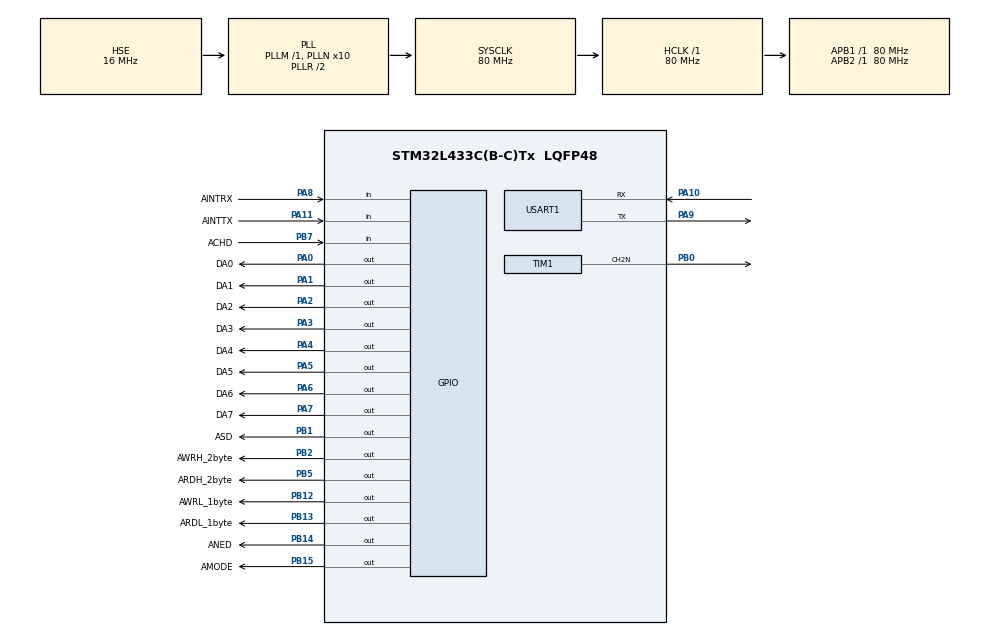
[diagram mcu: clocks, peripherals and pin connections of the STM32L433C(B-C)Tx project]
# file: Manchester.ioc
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Mcu.Family=STM32L4
Mcu.Name=STM32L433C(B-C)Tx
Mcu.Package=LQFP48
NVIC.PriorityGroup=NVIC_PRIORITYGROUP_4
PA0.GPIO_Label=DA0
PA0.Signal=GPIO_Output
PA1.GPIO_Label=DA1
PA1.Signal=GPIO_Output
PA10.Mode=Asynchronous
PA10.Signal=USART1_RX
PA11.GPIO_Label=AINTTX
PA11.Signal=GPIO_Input
PA2.GPIO_Label=DA2
PA2.Signal=GPIO_Output
PA3.GPIO_Label=DA3
PA3.Signal=GPIO_Output
PA4.GPIO_Label=DA4
PA4.Signal=GPIO_Output
PA5.GPIO_Label=DA5
PA5.Signal=GPIO_Output
PA6.GPIO_Label=DA6
PA6.Signal=GPIO_Output
PA7.GPIO_Label=DA7
PA7.Signal=GPIO_Output
PA8.GPIO_Label=AINTRX
PA8.Signal=GPIO_Input
PA9.Mode=Asynchronous
PA9.Signal=USART1_TX
PB0.Mode=PWM Generation2 CH2N
PB0.Signal=TIM1_CH2N
PB1.GPIO_Label=ASD
PB1.PinState=GPIO_PIN_RESET
PB1.Signal=GPIO_Output
PB12.GPIO_Label=AWRL_1byte
PB12.Signal=GPIO_Output
PB13.GPIO_Label=ARDL_1byte
PB13.Signal=GPIO_Output
PB14.GPIO_Label=ANED
PB14.Signal=GPIO_Output
PB15.GPIO_Label=AMODE
PB15.PinState=GPIO_PIN_RESET
PB15.Signal=GPIO_Output
PB2.GPIO_Label=AWRH_2byte
PB2.Signal=GPIO_Output
PB5.GPIO_Label=ARDH_2byte
PB5.Signal=GPIO_Output
PB7.GPIO_Label=ACHD
PB7.Signal=GPIO_Input
PH0-OSC_IN\ (PH0).Mode=HSE-External-Oscillator
PH0-OSC_IN\ (PH0).Signal=RCC_OSC_IN
PH1-OSC_OUT\ (PH1).Mode=HSE-External-Oscillator
PH1-OSC_OUT\ (PH1).Signal=RCC_OSC_OUT
ProjectManager.HeapSize=0x200
ProjectManager.StackSize=0x400
ProjectManager.TargetToolchain=STM32CubeIDE
RCC.ADCFreq_Value=64000000
RCC.AHBFreq_Value=80000000
RCC.APB1Freq_Value=80000000
RCC.APB1TimFreq_Value=80000000
RCC.APB2Freq_Value=80000000
RCC.APB2TimFreq_Value=80000000
RCC.CortexFreq_Value=80000000
RCC.HCLKFreq_Value=80000000
RCC.HSE_VALUE=16000000
RCC.HSI48_VALUE=48000000
RCC.HSI_VALUE=16000000
RCC.LSE_VALUE=32768
RCC.MSI_VALUE=4000000
RCC.PLLN=10
RCC.PLLSourceVirtual=RCC_PLLSOURCE_HSE
RCC.SYSCLKFreq_VALUE=80000000
RCC.SYSCLKSource=RCC_SYSCLKSOURCE_PLLCLK
RCC.USBFreq_Value=64000000
RCC.VCOOutputFreq_Value=160000000
TIM1.Channel-PWM\ Generation2\ CH2N=TIM_CHANNEL_2
TIM1.Period=79
TIM1.Prescaler=1
TIM1.Pulse-PWM\ Generation2\ CH2N=39
USART1.VirtualMode-Asynchronous=VM_ASYNC
VP_TIM1_VS_ClockSourceINT.Mode=Internal
board=custom

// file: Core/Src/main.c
/* USER CODE BEGIN Header */
/**
 ******************************************************************************
 * @file           : main.c
 * @brief          : Main program body
 ******************************************************************************
 * @attention
 *
 * Copyright (c) 2024 STMicroelectronics.
 * All rights reserved.
 *
 * This software is licensed under terms that can be found in the LICENSE file
 * in the root directory of this software component.
 * If no LICENSE file comes with this software, it is provided AS-IS.
 *
 ******************************************************************************
 */
/* USER CODE END Header */
#include "main.h"

TIM_HandleTypeDef htim1;

UART_HandleTypeDef huart1;

void SystemClock_Config(void);
static void MX_GPIO_Init(void);
static void MX_USART1_UART_Init(void);
static void MX_TIM1_Init(void);

int main(void)
{

  /* MCU Configuration--------------------------------------------------------*/

  /* Reset of all peripherals, Initializes the Flash interface and the Systick. */
  HAL_Init();

  /* USER CODE BEGIN Init */
//	HAL_GPIO_WritePin(GPIOB, AMODE_Pin ,GPIO_PIN_SET);
	HAL_Delay(1000);
  /* USER CODE END Init */

  /* Configure the system clock */
  SystemClock_Config();

  /* Initialize all configured peripherals */
  MX_GPIO_Init();
  MX_USART1_UART_Init();
  MX_TIM1_Init();
  /* USER CODE BEGIN 2 */
//	HAL_TIM_PWM_Start(&htim2, TIM_CHANNEL_4);
	HAL_TIMEx_PWMN_Start(&htim1, TIM_CHANNEL_2);
  /* USER CODE END 2 */

  /* Infinite loop */
  /* USER CODE BEGIN WHILE */
	int cnt = 0;
	while (1) {
		//pushDatesToPort(0b10101010, 0b10101010); // отправка по кабелю
		cnt = (cnt + 1)%4;
		const uint16_t aBuff[4] = { 0xAAAA, 0x0000, 0x5555, 0xFFFF };
		pushDatesToPort(aBuff[cnt] & 0xFF, (aBuff[cnt]>>8) & 0xFF); // отправка по кабелю

//		pushDatesToPort(0xFF, 0x00);
    /* USER CODE END WHILE */

    /* USER CODE BEGIN 3 */
		HAL_Delay(50);
	}
  /* USER CODE END 3 */
}

void SystemClock_Config(void)
{
  RCC_OscInitTypeDef RCC_OscInitStruct = {0};
  RCC_ClkInitTypeDef RCC_ClkInitStruct = {0};

  /** Configure the main internal regulator output voltage
  */
  if (HAL_PWREx_ControlVoltageScaling(PWR_REGULATOR_VOLTAGE_SCALE1) != HAL_OK)
  {
    Error_Handler();
  }

  /** Initializes the RCC Oscillators according to the specified parameters
  * in the RCC_OscInitTypeDef structure.
  */
  RCC_OscInitStruct.OscillatorType = RCC_OSCILLATORTYPE_HSE;
  RCC_OscInitStruct.HSEState = RCC_HSE_ON;
  RCC_OscInitStruct.PLL.PLLState = RCC_PLL_ON;
  RCC_OscInitStruct.PLL.PLLSource = RCC_PLLSOURCE_HSE;
  RCC_OscInitStruct.PLL.PLLM = 1;
  RCC_OscInitStruct.PLL.PLLN = 10;
  RCC_OscInitStruct.PLL.PLLP = RCC_PLLP_DIV7;
  RCC_OscInitStruct.PLL.PLLQ = RCC_PLLQ_DIV2;
  RCC_OscInitStruct.PLL.PLLR = RCC_PLLR_DIV2;
  if (HAL_RCC_OscConfig(&RCC_OscInitStruct) != HAL_OK)
  {
    Error_Handler();
  }

  /** Initializes the CPU, AHB and APB buses clocks
  */
  RCC_ClkInitStruct.ClockType = RCC_CLOCKTYPE_HCLK|RCC_CLOCKTYPE_SYSCLK
                              |RCC_CLOCKTYPE_PCLK1|RCC_CLOCKTYPE_PCLK2;
  RCC_ClkInitStruct.SYSCLKSource = RCC_SYSCLKSOURCE_PLLCLK;
  RCC_ClkInitStruct.AHBCLKDivider = RCC_SYSCLK_DIV1;
  RCC_ClkInitStruct.APB1CLKDivider = RCC_HCLK_DIV1;
  RCC_ClkInitStruct.APB2CLKDivider = RCC_HCLK_DIV1;

  if (HAL_RCC_ClockConfig(&RCC_ClkInitStruct, FLASH_LATENCY_4) != HAL_OK)
  {
    Error_Handler();
  }
}

static void MX_TIM1_Init(void)
{

  TIM_ClockConfigTypeDef sClockSourceConfig = {0};
  TIM_MasterConfigTypeDef sMasterConfig = {0};
  TIM_OC_InitTypeDef sConfigOC = {0};
  TIM_BreakDeadTimeConfigTypeDef sBreakDeadTimeConfig = {0};

  htim1.Instance = TIM1;
  htim1.Init.Prescaler = 1;
  htim1.Init.CounterMode = TIM_COUNTERMODE_UP;
  htim1.Init.Period = 79;
  htim1.Init.ClockDivision = TIM_CLOCKDIVISION_DIV1;
  htim1.Init.RepetitionCounter = 0;
  htim1.Init.AutoReloadPreload = TIM_AUTORELOAD_PRELOAD_DISABLE;
  if (HAL_TIM_Base_Init(&htim1) != HAL_OK)
  {
    Error_Handler();
  }
  sClockSourceConfig.ClockSource = TIM_CLOCKSOURCE_INTERNAL;
  if (HAL_TIM_ConfigClockSource(&htim1, &sClockSourceConfig) != HAL_OK)
  {
    Error_Handler();
  }
  if (HAL_TIM_PWM_Init(&htim1) != HAL_OK)
  {
    Error_Handler();
  }
  sMasterConfig.MasterOutputTrigger = TIM_TRGO_RESET;
  sMasterConfig.MasterOutputTrigger2 = TIM_TRGO2_RESET;
  sMasterConfig.MasterSlaveMode = TIM_MASTERSLAVEMODE_DISABLE;
  if (HAL_TIMEx_MasterConfigSynchronization(&htim1, &sMasterConfig) != HAL_OK)
  {
    Error_Handler();
  }
  sConfigOC.OCMode = TIM_OCMODE_PWM1;
  sConfigOC.Pulse = 39;
  sConfigOC.OCPolarity = TIM_OCPOLARITY_HIGH;
  sConfigOC.OCNPolarity = TIM_OCNPOLARITY_HIGH;
  sConfigOC.OCFastMode = TIM_OCFAST_DISABLE;
  sConfigOC.OCIdleState = TIM_OCIDLESTATE_RESET;
  sConfigOC.OCNIdleState = TIM_OCNIDLESTATE_RESET;
  if (HAL_TIM_PWM_ConfigChannel(&htim1, &sConfigOC, TIM_CHANNEL_2) != HAL_OK)
  {
    Error_Handler();
  }
  sBreakDeadTimeConfig.OffStateRunMode = TIM_OSSR_DISABLE;
  sBreakDeadTimeConfig.OffStateIDLEMode = TIM_OSSI_DISABLE;
  sBreakDeadTimeConfig.LockLevel = TIM_LOCKLEVEL_OFF;
  sBreakDeadTimeConfig.DeadTime = 0;
  sBreakDeadTimeConfig.BreakState = TIM_BREAK_DISABLE;
  sBreakDeadTimeConfig.BreakPolarity = TIM_BREAKPOLARITY_HIGH;
  sBreakDeadTimeConfig.BreakFilter = 0;
  sBreakDeadTimeConfig.Break2State = TIM_BREAK2_DISABLE;
  sBreakDeadTimeConfig.Break2Polarity = TIM_BREAK2POLARITY_HIGH;
  sBreakDeadTimeConfig.Break2Filter = 0;
  sBreakDeadTimeConfig.AutomaticOutput = TIM_AUTOMATICOUTPUT_DISABLE;
  if (HAL_TIMEx_ConfigBreakDeadTime(&htim1, &sBreakDeadTimeConfig) != HAL_OK)
  {
    Error_Handler();
  }
  HAL_TIM_MspPostInit(&htim1);

}

static void MX_USART1_UART_Init(void)
{

  huart1.Instance = USART1;
  huart1.Init.BaudRate = 115200;
  huart1.Init.WordLength = UART_WORDLENGTH_8B;
  huart1.Init.StopBits = UART_STOPBITS_1;
  huart1.Init.Parity = UART_PARITY_NONE;
  huart1.Init.Mode = UART_MODE_TX_RX;
  huart1.Init.HwFlowCtl = UART_HWCONTROL_NONE;
  huart1.Init.OverSampling = UART_OVERSAMPLING_16;
  huart1.Init.OneBitSampling = UART_ONE_BIT_SAMPLE_DISABLE;
  huart1.AdvancedInit.AdvFeatureInit = UART_ADVFEATURE_NO_INIT;
  if (HAL_UART_Init(&huart1) != HAL_OK)
  {
    Error_Handler();
  }

}

static void MX_GPIO_Init(void)
{
  GPIO_InitTypeDef GPIO_InitStruct = {0};

  /* GPIO Ports Clock Enable */
  __HAL_RCC_GPIOH_CLK_ENABLE();
  __HAL_RCC_GPIOA_CLK_ENABLE();
  __HAL_RCC_GPIOB_CLK_ENABLE();

  /*Configure GPIO pin Output Level */
  HAL_GPIO_WritePin(GPIOA, DA0_Pin|DA1_Pin|DA2_Pin|DA3_Pin
                          |DA4_Pin|DA5_Pin|DA6_Pin|DA7_Pin, GPIO_PIN_RESET);

  /*Configure GPIO pin Output Level */
  HAL_GPIO_WritePin(GPIOB, ASD_Pin|AWRH_2byte_Pin|AWRL_1byte_Pin|ARDL_1byte_Pin
                          |ANED_Pin|AMODE_Pin|ARDH_2byte_Pin, GPIO_PIN_RESET);

  /*Configure GPIO pins : DA0_Pin DA1_Pin DA2_Pin DA3_Pin
                           DA4_Pin DA5_Pin DA6_Pin DA7_Pin */
  GPIO_InitStruct.Pin = DA0_Pin|DA1_Pin|DA2_Pin|DA3_Pin
                          |DA4_Pin|DA5_Pin|DA6_Pin|DA7_Pin;
  GPIO_InitStruct.Mode = GPIO_MODE_OUTPUT_PP;
  GPIO_InitStruct.Pull = GPIO_NOPULL;
  GPIO_InitStruct.Speed = GPIO_SPEED_FREQ_LOW;
  HAL_GPIO_Init(GPIOA, &GPIO_InitStruct);

  /*Configure GPIO pins : ASD_Pin AWRH_2byte_Pin AWRL_1byte_Pin ARDL_1byte_Pin
                           ANED_Pin AMODE_Pin ARDH_2byte_Pin */
  GPIO_InitStruct.Pin = ASD_Pin|AWRH_2byte_Pin|AWRL_1byte_Pin|ARDL_1byte_Pin
                          |ANED_Pin|AMODE_Pin|ARDH_2byte_Pin;
  GPIO_InitStruct.Mode = GPIO_MODE_OUTPUT_PP;
  GPIO_InitStruct.Pull = GPIO_NOPULL;
  GPIO_InitStruct.Speed = GPIO_SPEED_FREQ_LOW;
  HAL_GPIO_Init(GPIOB, &GPIO_InitStruct);

  /*Configure GPIO pins : AINTRX_Pin AINTTX_Pin */
  GPIO_InitStruct.Pin = AINTRX_Pin|AINTTX_Pin;
  GPIO_InitStruct.Mode = GPIO_MODE_INPUT;
  GPIO_InitStruct.Pull = GPIO_NOPULL;
  HAL_GPIO_Init(GPIOA, &GPIO_InitStruct);

  /*Configure GPIO pin : ACHD_Pin */
  GPIO_InitStruct.Pin = ACHD_Pin;
  GPIO_InitStruct.Mode = GPIO_MODE_INPUT;
  GPIO_InitStruct.Pull = GPIO_NOPULL;
  HAL_GPIO_Init(ACHD_GPIO_Port, &GPIO_InitStruct);

/* USER CODE BEGIN MX_GPIO_Init_2 */
	GPIO_InitStruct.Pin =  ACHD_Pin;
		GPIO_InitStruct.Mode = GPIO_MODE_INPUT;
		GPIO_InitStruct.Pull = GPIO_NOPULL;
		HAL_GPIO_Init(GPIOB, &GPIO_InitStruct);
/* USER CODE END MX_GPIO_Init_2 */
}

void Error_Handler(void)
{
	__disable_irq();
	while (1) {
	}
}
